# IMM100A register map
Vendor: Infineon; File version: 0.8.0 (Reference Manual v0.8.0)
CPU: CM0 r0p0, little endian, no MPU, no FPU, 2 interrupt priority bits
Registers are 32-bit, read-write, reset 0x0 unless marked. A register's access mark holds for its fields unless they carry their own. Offsets are from the block's base; [hi:lo] are bit positions.

## WDT — Watch Dog Timer
Base 0x40020000
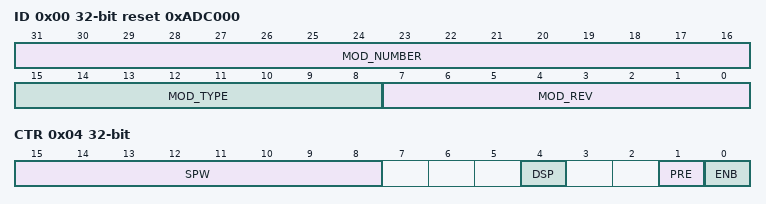
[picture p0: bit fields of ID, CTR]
0x00 ID ro reset 0xADC000 (reset mask 0xFFFFFF00) — WDT Module ID Register
  [31:16] MOD_NUMBER — Module Number Value
  [15:8] MOD_TYPE — Module Type
  [7:0] MOD_REV — Module Revision Number
0x04 CTR — WDT Control Register
  [15:8] SPW — Service Indication Pulse Width
  [4] DSP — Debug Suspend
  [1] PRE — Pre-warning
  [0] ENB — Enable
0x08 SRV wo — WDT Service Register
  [31:0] SRV — Service
0x0C TIM ro — WDT Timer Register
  [31:0] TIM — Timer Value
0x10 WLB — WDT Window Lower Bound Register
  [31:0] WLB — Window Lower Bound
0x14 WUB reset 0xFFFFFFFF — WDT Window Upper Bound Register
  [31:0] WUB — Window Upper Bound
0x18 WDTSTS ro — WDT Status Register
  [0] ALMS — Pre-warning Alarm
0x1C WDTCLR wo — WDT Clear Register
  [0] ALMC — Pre-warning Alarm

## RTC — Real Time Clock
Base 0x40010A00
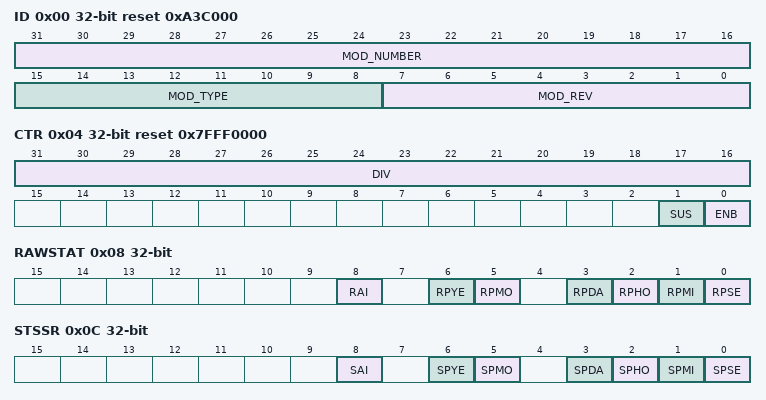
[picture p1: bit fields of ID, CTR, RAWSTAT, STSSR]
0x00 ID ro reset 0xA3C000 (reset mask 0xFFFFFF00) — RTC Module ID Register
  [31:16] MOD_NUMBER — Module Number Value
  [15:8] MOD_TYPE — Module Type
  [7:0] MOD_REV — Module Revision Number
0x04 CTR reset 0x7FFF0000 — RTC Control Register
  [31:16] DIV — Divider Value
  [1] SUS — Debug Suspend Control
  [0] ENB — RTC Module Enable
0x08 RAWSTAT ro — RTC Raw Service Request Register
  [8] RAI — Alarm Service Request
  [6] RPYE — Raw Periodic Years Service Request
  [5] RPMO — Raw Periodic Months Service Request
  [3] RPDA — Raw Periodic Days Service Request
  [2] RPHO — Raw Periodic Hours Service Request
  [1] RPMI — Raw Periodic Minutes Service Request
  [0] RPSE — Raw Periodic Seconds Service Request
0x0C STSSR ro — RTC Service Request Status Register
  [8] SAI — Alarm Service Request Status after masking
  [6] SPYE — Periodic Years Service Request Status after masking
  [5] SPMO — Periodic Months Service Request Status after masking
  [3] SPDA — Periodic Days Service Request Status after masking
  [2] SPHO — Periodic Hours Service Request Status after masking
  [1] SPMI — Periodic Minutes Service Request Status after masking
  [0] SPSE — Periodic Seconds Service Request Status after masking
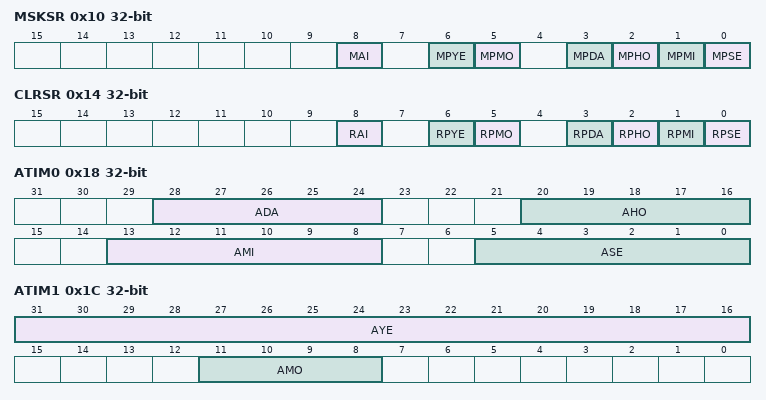
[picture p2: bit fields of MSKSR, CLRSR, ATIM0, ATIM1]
0x10 MSKSR — RTC Service Request Mask Register
  [8] MAI — Alarm Interrupt Mask
  [6] MPYE — Periodic Years Interrupt Mask
  [5] MPMO — Periodic Months Interrupt Mask
  [3] MPDA — Periodic Days Interrupt Mask
  [2] MPHO — Periodic Hours Interrupt Mask
  [1] MPMI — Periodic Minutes Interrupt Mask
  [0] MPSE — Periodic Seconds Interrupt Mask
0x14 CLRSR wo — RTC Clear Service Request Register
  [8] RAI — Raw Alarm Interrupt Clear
  [6] RPYE — Raw Periodic Years Interrupt Clear
  [5] RPMO — Raw Periodic Months Interrupt Clear
  [3] RPDA — Raw Periodic Days Interrupt Clear
  [2] RPHO — Raw Periodic Hours Interrupt Clear
  [1] RPMI — Raw Periodic Minutes Interrupt Clear
  [0] RPSE — Raw Periodic Seconds Interrupt Clear
0x18 ATIM0 — RTC Alarm Time Register 0
  [28:24] ADA — Alarm Days Compare Value
  [20:16] AHO — Alarm Hours Compare Value
  [13:8] AMI — Alarm Minutes Compare Value
  [5:0] ASE — Alarm Seconds Compare Value
0x1C ATIM1 — RTC Alarm Time Register 1
  [31:16] AYE — Alarm Year Compare Value
  [11:8] AMO — Alarm Month Compare Value
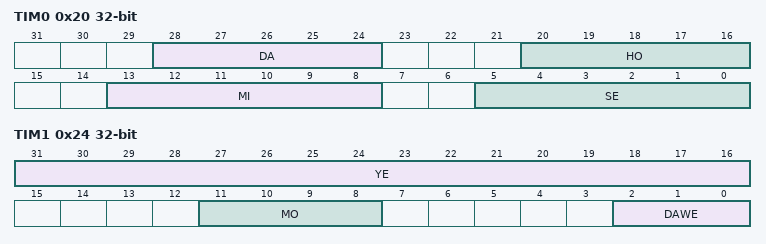
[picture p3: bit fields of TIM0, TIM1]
0x20 TIM0 — RTC Time Register 0
  [28:24] DA — Days Time Value
  [20:16] HO — Hours Time Value
  [13:8] MI — Minutes Time Value
  [5:0] SE — Seconds Time Value
0x24 TIM1 — RTC Time Register 1
  [31:16] YE — Year Time Value
  [11:8] MO — Month Time Value
  [2:0] DAWE — Days of Week Time Value

## PRNG — PRNG Unit
Base 0x48020000
0x00 WORD 16-bit — PRNG Word Register
  [15:0] RDATA — Random Data
0x04 CHK 16-bit ro — PRNG Status Check Register
  [0] RDV — Random Data / Key Valid Flag
    0=New random data block is not yet ready to be read. In ) this flag is set to #0 while loading is in progress.; 1=Random data block is valid. In key loading mode this value indicates that the next partial key word can be written to PRNG_WORD.
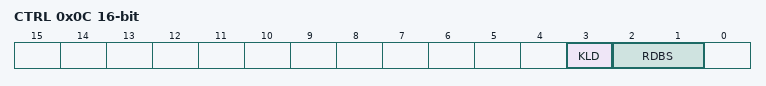
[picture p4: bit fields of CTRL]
0x0C CTRL 16-bit — PRNG Control Register
  [3] KLD — Key Load Operation Mode
    0=Streaming mode (default); 1=Key loading mode
  [2:1] RDBS — Random Data Block Size
    0=Reset state (no random data block size defined), value of PRNG_WORD is undefined; 1=8 bits in PRNG_WORD.RDATA[7:0]; 2=16 bits in PRNG_WORD.RDATA[15:0]

## Notices in the file
Copyright (C) 2017 Infineon Technologies AG. All rights reserved.
Infineon Technologies AG (Infineon) is supplying this software for use with
Infineon's microcontrollers.  This file can be freely distributed within
development tools that are supporting such microcontrollers.
THIS SOFTWARE IS PROVIDED "AS IS".  NO WARRANTIES, WHETHER EXPRESS, IMPLIED
OR STATUTORY, INCLUDING, BUT NOT LIMITED TO, IMPLIED WARRANTIES OF
MERCHANTABILITY AND FITNESS FOR A PARTICULAR PURPOSE APPLY TO THIS SOFTWARE.
INFINEON SHALL NOT, IN ANY CIRCUMSTANCES, BE LIABLE FOR SPECIAL, INCIDENTAL,
OR CONSEQUENTIAL DAMAGES, FOR ANY REASON WHATSOEVER.
